# RT584ZCM33 register map
Series: ARMv8-M Mainline; File version: 1.0
CPU: CM33 r0p0, little endian, MPU, no FPU, VTOR, 3 interrupt priority bits
Registers are 32-bit, read-write, reset 0x0 unless marked. A register's access mark holds for its fields unless they carry their own. Offsets are from the block's base; [hi:lo] are bit positions.

## SWIRQ0_Non-Secure — SWIRQ0 Non-Secure Register block
Base 0x40030000
Same registers: SWIRQ1_Non-Secure 0x40031000, SWIRQ0_Secure 0x50030000, SWIRQ1_Secure 0x50031000
0x00 SOFT_SET_IRQ_REG wo — Write 1 to trigger the corresponding SW IRQ
0x04 SOFT_CLR_IRQ_REG wo — Write 1 to clear the corresponding SW IRQ
0x08 SOFT_IRQ_STATE_REG ro — The status of SW IRQ
0x0C SOFT_IRQ_DATA_REG — Data register for software use.

## CRYPTO_Non-Secure — CRYPTO Non-Secure Register block
Base 0x60000000
Same registers: CRYPTO_Secure 0x70000000
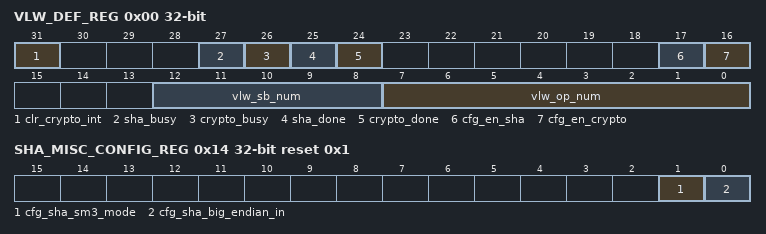
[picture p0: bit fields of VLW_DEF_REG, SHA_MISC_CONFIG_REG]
0x00 VLW_DEF_REG — vlw def
  [31] clr_crypto_int wo — Write 1 after crypto_done/sha_done to clear interrupt and crypto_done/sha_done
    0=B_31 (Write 1 after crypto_done/sha_done to clear interrupt and crypto_done/sha_done)
  [27] sha_busy ro — Asserts after sha256 engine start. It returns to 0 when sha_done.
    0=B_27 (Asserts after sha256 engine start. It returns to 0 when sha_done.)
  [26] crypto_busy ro — Asserts after crypto engine start. It returns to 0 when crypto_done.
    0=B_26 (Asserts after crypto engine start. It returns to 0 when crypto_done.)
  [25] sha_done ro — Asserts after sha256 engine finish. Write 1 to clr_crypto_int to clear sha_done.
    0=B_25 (Asserts after sha256 engine finish. Write 1 to clr_crypto_int to clear sha_done.)
  [24] crypto_done ro — Asserts after crypto engine finish. Write 1 to clr_crypto_int to clear crypto_done.
    0=B_24 (Asserts after crypto engine finish. Write 1 to clr_crypto_int to clear crypto_done.)
  [17] cfg_en_sha wo — Enable of sha256 engine 0: disable sha256 1: enable sha256
    0=B_17 (Enable of sha256 engine 0: disable sha256 1: enable sha256)
  [16] cfg_en_crypto wo — Enable of crypto engine 0: disable crypto 1: enable crypto
    0=B_16 (Enable of crypto engine 0: disable crypto 1: enable crypto)
  [12:8] vlw_sb_num — Sign bit position at most significant word.
    0=B_8_to_12 (Sign bit position at most significant word.)
  [7:0] vlw_op_num — number - 1 of long word(32bit for ECC) Exp: p256 --> (256/32) = 8, p521 --> (521/32) = 16.28125 -->16
    0=B_0_to_7 (number - 1 of long word(32bit for ECC) Exp: p256 --> (256/32) = 8, p521 --> (521/32) = 16.28125 -->16)
0x04 SHA_DIGEST_BASE_REG reset 0x100 — sha digest base
  [10:0] cfg_sha_digest_base — Base address of digest. (h0~h7). This value should be multiply of 4. The complete address is limited as (0x40041800 + cfg_sha_digest_base). HW takes only 11 bits to save register. This memory costs 32 bytes. SW prepare initial digest here for the first time of data blocks.
0x08 SHA_K_BASE_REG — sha k base
  [10:0] cfg_sha_k_base — Base address of constant K. This value should be multply of 4. The complete address is limited as (0x40041800 + cfg_sha_k_base). HW takes only 11 bits to save register. This memory costs 256 bytes. SW prepare K[0..63] here for the first time.
0x0C SHA_DMA_BASE_REG reset 0x20008000 — Base address of sha DMA. SW prepare data for sha256 here.
0x10 SHA_DMA_LENGTH_REG reset 0x80 — sha dma length
  [15:0] cfg_sha_dma_length — Length of sha DMA. This value should be muliply of 64.
0x14 SHA_MISC_CONFIG_REG reset 0x1 — sha misc config
  [1] cfg_sha_sm3_mode — Mode of sha engine 0: sha256 mode 1: sm3 mode
    0=B_1_ITEM0 (sha256 mode); 1=B_1_ITEM1 (sm3 mode)
  [0] cfg_sha_big_endian_in — Note that the last 2 words of spec are big enidan together, which HW can't handle. SW should take care the last 2 words according to document. 0: HW parse data from DMA with little endian. 1: HW parse data from DMA with BIG endian.
    0=B_0_ITEM0 (HW parse data from DMA with little endian.); 1=B_0_ITEM1 (HW parse data from DMA with BIG endian.)
